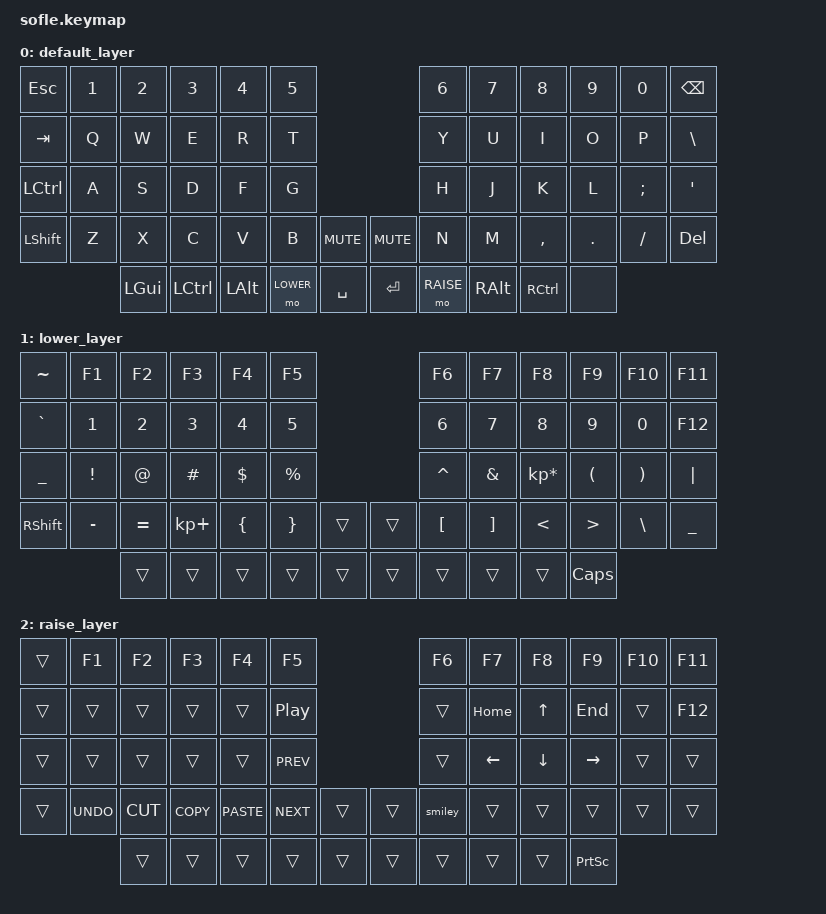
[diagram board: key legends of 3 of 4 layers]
/*
 * Copyright (c) 2020 The ZMK Contributors
 *
 * SPDX-License-Identifier: MIT
 */
#define DEFAULT 0
#define LOWER   1
#define RAISE   2
#define ADJUST  3

#include <behaviors.dtsi>
#include <dt-bindings/zmk/keys.h>
#include <dt-bindings/zmk/bt.h>

&left_encoder { resolution = <1>; };
&right_encoder { resolution = <1>; };

&mt { tapping-term-ms = <2000>; };

/ {
    // add easter egg
    macros {
        smiley: smiley {
            label = "EASTER_SMILEY";
            compatible = "zmk,behavior-macro";
            #binding-cells = <0>;
            bindings
                = <&macro_tap &kp COLON &kp RPAR>
                ;
        };
    };

    // Activate ADJUST layer by pressing raise and lower
    conditional_layers {
        compatible = "zmk,conditional-layers";
        adjust_layer {
            if-layers = <LOWER RAISE>;
            then-layer = <ADJUST>;
        };
    };

    keymap {
        compatible = "zmk,keymap";

        default_layer {
// ------------------------------------------------------------------------------------------------------------
// |  ESC  |  1  |  2  |  3   |  4   |  5   |                   |  6   |  7    |  8    |  9    |   0   | BKSPC  |
// |  TAB  |  Q  |  W  |  E   |  R   |  T   |                   |  Y   |  U    |  I    |  O    |   P   | \      |
// | CAPS  |  A  |  S  |  D   |  F   |  G   |                   |  H   |  J    |  K    |  L    |   ;   |   '    |
// | SHIFT |  Z  |  X  |  C   |  V   |  B   |  MUTE  |  | MUTE  |  N   |  M    |  ,    |  .    |   /   | DELETE |
//               | GUI | CTRL | ALT  | LOWER|  SPACE |  | ENTER | RAISE| ALT   | CTRL   | CAPS (on hold) |
            bindings = <
&kp ESC   &kp N1 &kp N2   &kp N3    &kp N4    &kp N5                            &kp N6      &kp N7      &kp N8      &kp N9   &kp N0   &kp BSPC
&kp TAB   &kp Q  &kp W    &kp E     &kp R     &kp T                             &kp Y       &kp U       &kp I       &kp O    &kp P    &kp BSLH
&kp LCTRL &kp A  &kp S    &kp D     &kp F     &kp G                             &kp H       &kp J       &kp K       &kp L    &kp SEMI &kp SQT
&kp LSHFT &kp Z  &kp X    &kp C     &kp V     &kp B     &kp C_MUTE &kp C_MUTE   &kp N       &kp M       &kp COMMA   &kp DOT  &kp FSLH &kp DELETE
                 &kp LGUI &kp LCTRL &kp LALT  &mo LOWER &kp SPACE  &kp RET      &mo RAISE   &kp RALT    &kp RCTRL   &none
            >;

            sensor-bindings = <
                &inc_dec_kp UP DOWN
                &inc_dec_kp C_VOL_DN C_VOL_UP
            >;
        };

        lower_layer {
// ------------------------------------------------------------------------------------------------------------
// | ~     |  F1 |  F2 |  F3  |  F4  |  F5  |                   |  F6  |  F7   |  F8   |  F9  |  F10  |  F11  |
// | `     |   1 |   2 |   3  |   4  |   5  |                   |   6  |   7   |   8   |   9  |    0  |  F12  |
// |       |  !  |  @  |  #   |  $   |  %   |                   |  ^   |  &    |  *    |  (   |   )   |   |   |
// |       |  -  |  =  |  +   |  {   |  }   |        |  |       |  [   |  ]    |  ;    |  :   |   \   |   _   |
//               |     |      |      |      |        |  |       |      |       |       |      |
            bindings = <
&kp TILDE   &kp F1      &kp F2      &kp F3      &kp F4      &kp F5                      &kp F6      &kp F7      &kp F8          &kp F9      &kp F10   &kp F11
&kp GRAVE   &kp N1      &kp N2      &kp N3      &kp N4      &kp N5                      &kp N6      &kp N7      &kp N8          &kp N9      &kp N0    &kp F12
&kp UNDER   &kp EXCL    &kp AT      &kp HASH    &kp DLLR    &kp PRCNT                   &kp CARET   &kp AMPS    &kp KP_MULTIPLY &kp LPAR    &kp RPAR  &kp PIPE
&kp RSHFT   &kp MINUS   &kp EQUAL   &kp KP_PLUS &kp LBRC    &kp RBRC    &trans  &trans  &kp LBKT    &kp RBKT    &kp LT          &kp GT      &kp BSLH  &kp UNDER
                        &trans      &trans      &trans      &trans      &trans  &trans  &trans      &trans      &trans          &kp CAPS
            >;  

            sensor-bindings = <&inc_dec_kp C_VOL_UP C_VOL_DN &inc_dec_kp PG_DN PG_UP>;
        };


        raise_layer {
            bindings = <
&trans &kp F1       &kp F2      &kp F3      &kp F4      &kp F5                      &kp F6          &kp F7          &kp F8          &kp F9          &kp F10         &kp F11
&trans &trans       &trans      &trans      &trans      &kp C_PP                    &trans          &kp HOME        &kp UP          &kp END         &trans          &kp F12
&trans &trans       &trans      &trans      &trans      &kp K_PREV                  &trans          &kp LEFT        &kp DOWN        &kp RIGHT       &trans          &trans 
&trans &kp K_UNDO   &kp K_CUT   &kp K_COPY  &kp K_PASTE &kp K_NEXT  &trans  &trans  &smiley         &trans          &trans          &trans          &trans          &trans
                    &trans      &trans      &trans      &trans      &trans  &trans  &trans          &trans          &trans          &kp PSCRN
            >;

            sensor-bindings = <&inc_dec_kp RIGHT LEFT &inc_dec_kp C_BRI_DN C_BRI_UP>;
        };

// ------------------------------------------------------------------------------------------------------------
// |BTCLR | BT1   | BT2   |  BT3  |  BT4  |  BT5  |                |      |      |       |      |       |       |
// |      |       |       |       |       |       |                |      |      |       |      |       |       |
// |      |       |       |       |       |       |                |      |      |       |      |       |       |
// |      |       |       |       |       |       |       | |      |      |       |      |       |       |
//                |       |       |       |       |       | |      |      |      |       |      |

        adjust_layer {
            bindings = <
&bt BT_CLR  &bt BT_SEL 0    &bt BT_SEL 1    &bt BT_SEL 2    &bt BT_SEL 3    &bt BT_SEL 4                          &none &none &none &none &none &none
&none       &none           &none           &none           &none           &none                                 &none &none &none &none &none &none
&bootloader &none           &none           &none           &none                                                 &none &none &none &none &none &bootloader
&none       &none           &none           &none           &none           &none               &none  &none      &none &none &none &none &none &none
                            &none           &none           &none           &none               &none  &none      &none &none &none &none
            >;
        };

    };
};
